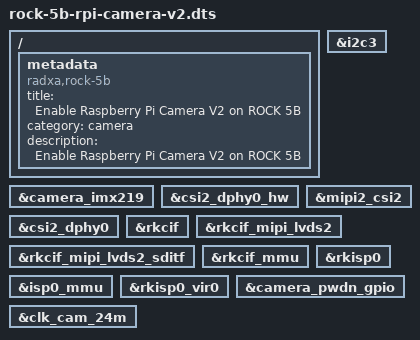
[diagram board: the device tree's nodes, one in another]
/dts-v1/;
/plugin/;

/ {
	metadata {
		title ="Enable Raspberry Pi Camera V2 on ROCK 5B";
		compatible = "radxa,rock-5b", "rockchip,rk3588";
		category = "camera";
		description = "Enable Raspberry Pi Camera V2 on ROCK 5B";
	};

	fragment@0 {
		target = <&i2c3>;

		__overlay__ {
			status = "okay";
		};
	};

	fragment@1 {
		target = <&camera_imx219>;

		__overlay__ {
			status = "okay";
		};
	};

	fragment@2 {
		target = <&csi2_dphy0_hw>;

		__overlay__ {
			status = "okay";
		};
	};

	fragment@3 {
		target = <&csi2_dphy0>;

		__overlay__ {
			status = "okay";
		};
	};

	fragment@4 {
		target = <&mipi2_csi2>;

		__overlay__ {
			status = "okay";
		};
	};

	fragment@5 {
		target = <&rkcif>;

		__overlay__ {
			status = "okay";
		};
	};

	fragment@6 {
		target = <&rkcif_mipi_lvds2>;

		__overlay__ {
			status = "okay";
		};
	};

	fragment@7 {
		target = <&rkcif_mipi_lvds2_sditf>;

		__overlay__ {
			status = "okay";
		};
	};

	fragment@8 {
		target = <&rkcif_mmu>;

		__overlay__ {
			status = "okay";
		};
	};

	fragment@9 {
		target = <&isp0_mmu>;

		__overlay__ {
			status = "okay";
		};
	};

	fragment@10 {
		target = <&rkisp0>;

		__overlay__ {
			status = "okay";
		};
	};

	fragment@11 {
		target = <&rkisp0_vir0>;

		__overlay__ {
			status = "okay";
		};
	};

	fragment@12 {
		target = <&camera_pwdn_gpio>;

		__overlay__ {
			status = "okay";
		};
	};

	fragment@13 {
		target = <&clk_cam_24m>;

		__overlay__ {
			status = "okay";
		};
	};
};
